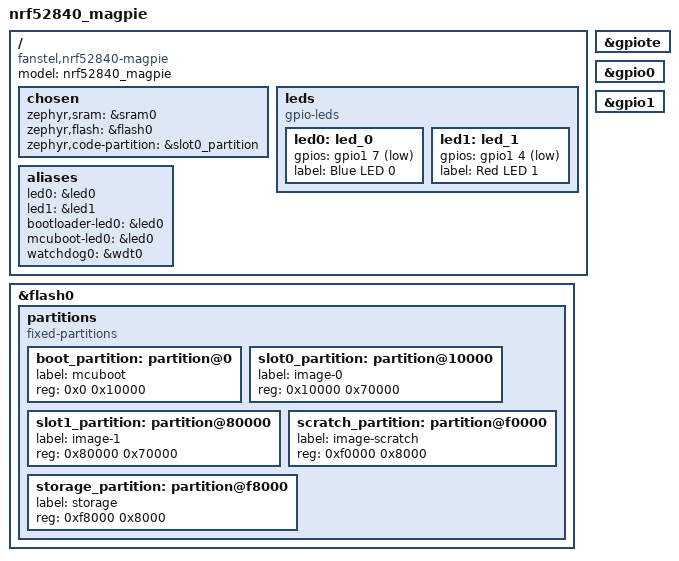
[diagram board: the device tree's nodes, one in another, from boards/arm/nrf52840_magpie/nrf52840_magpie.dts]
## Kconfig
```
# Copyright (c) 2021 Nordic Semiconductor ASA
# SPDX-License-Identifier: Apache-2.0

mainmenu "Nordic SYSTEM_OFF demo"

config APP_RETENTION
	bool "State retention in system off"
	depends on (SOC_COMPATIBLE_NRF52X || SOC_NRF52840) && CRC
	help
	  On some Nordic chips this application supports retaining
	  memory while in system off.  Select this to enable the
	  feature.

source "Kconfig.zephyr"
```

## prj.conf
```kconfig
# Copyright (c) 2024 Nordic Semiconductor ASA
# SPDX-License-Identifier: Apache-2.0

CONFIG_PM_DEVICE=y
CONFIG_GPIO=y
CONFIG_CRC=y
CONFIG_POWEROFF=y

CONFIG_CORTEX_M_DEBUG_MONITOR_HOOK=y
CONFIG_DEBUG_THREAD_INFO=y
CONFIG_SEGGER_DEBUGMON=y
CONFIG_DEBUG_OPTIMIZATIONS=y
CONFIG_KERNEL_BIN_NAME="nrf52840_magpie"

CONFIG_CLOCK_CONTROL_NRF_K32SRC_EXT_FULL_SWING=y
CONFIG_CLOCK_CONTROL_NRF_K32SRC_20PPM=y
CONFIG_CLOCK_CONTROL_FIXED_RATE_CLOCK=y

# Enable retained data feature
CONFIG_APP_RETENTION=y
```

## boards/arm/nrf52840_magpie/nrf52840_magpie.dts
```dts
// Copyright (c) 2024 Nordic Semiconductor ASA
// SPDX-License-Identifier: Apache-2.0

/dts-v1/;
#include <nordic/nrf52840_qfaa.dtsi>

/ {
	model = "nrf52840_magpie";
	compatible = "fanstel,nrf52840-magpie";

	chosen {
		zephyr,sram = &sram0;
		zephyr,flash = &flash0;
		zephyr,code-partition = &slot0_partition;
	};

	leds {
		compatible = "gpio-leds";
		led0: led_0 {
			gpios = <&gpio1 7 GPIO_ACTIVE_LOW>;
			label = "Blue LED 0";
		};
		led1: led_1 {
			gpios = <&gpio1 4 GPIO_ACTIVE_LOW>;
			label = "Red LED 1";
		};
	};

	aliases {
		led0 = &led0;
		led1 = &led1;
		bootloader-led0 = &led0;
		mcuboot-led0 = &led0;
		watchdog0 = &wdt0;
	};
};

&gpiote {
	status = "okay";
};

&gpio0 {
	status = "okay";
};

&gpio1 {
	status = "okay";
};

&flash0 {
	partitions {
		compatible = "fixed-partitions";
		#address-cells = <1>;
		#size-cells = <1>;

		boot_partition: partition@0 {
			label = "mcuboot";
			reg = <0x0 0x10000>;
		};
		slot0_partition: partition@10000 {
			label = "image-0";
			reg = <0x10000 0x70000>;
		};
		slot1_partition: partition@80000 {
			label = "image-1";
			reg = <0x80000 0x70000>;
		};
		scratch_partition: partition@f0000 {
			label = "image-scratch";
			reg = <0xf0000 0x8000>;
		};
		storage_partition: partition@f8000 {
			label = "storage";
			reg = <0xf8000 0x8000>;
		};
	};
};
```

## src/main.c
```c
/*
 * Copyright (c) 2019 Nordic Semiconductor ASA
 *
 * SPDX-License-Identifier: Apache-2.0
 */

#include "retained.h"

#include <inttypes.h>
#include <stdio.h>

#include <zephyr/device.h>
#include <zephyr/drivers/gpio.h>
#include <zephyr/kernel.h>
#include <zephyr/pm/device.h>
#include <zephyr/sys/poweroff.h>
#include <zephyr/sys/util.h>

#include <hal/nrf_gpio.h>

/* 1000 msec = 1 sec */
#define SLEEP_TIME_MS   100
/* The devicetree node identifier for the "led0" alias. */
#define LED0_NODE DT_ALIAS(led0)
/* The devicetree node identifier for the "led0" alias. */
#define LED1_NODE DT_ALIAS(led1)

static const struct gpio_dt_spec led_blue = GPIO_DT_SPEC_GET(LED0_NODE, gpios);
static const struct gpio_dt_spec led_red = GPIO_DT_SPEC_GET(LED1_NODE, gpios);
// static const struct gpio_dt_spec sw0 = GPIO_DT_SPEC_GET(DT_ALIAS(sw0), gpios);

/* LED pin definitions (from devicetree) */
#define LED_BLUE_PIN  7   /* P1.7 */
#define LED_RED_PIN   4   /* P1.4 */

/**
 * @brief Disconnect all GPIO pins to High-Z state
 * 
 * Sets all GPIO pins to input with no pull resistors (high impedance).
 * This prevents the nRF from interfering with shared bus lines when sleeping.
 * Exceptions:
 *   - P1.13: Output LOW
 *   - P1.14: Input
 *   - P1.4 (Red LED): Preserved
 *   - P1.7 (Blue LED): Preserved
 */
static void disconnect_all_gpios(void)
{
	/* Port 0: pins 0-31 */
	for (uint32_t pin = 0; pin < 32; pin++) {
		nrf_gpio_cfg_default(NRF_GPIO_PIN_MAP(0, pin));
	}
	/* Port 1: pins 0-15 (nRF52840 has 48 GPIOs total) */
	for (uint32_t pin = 0; pin < 16; pin++) {
		/* Skip P1.13, P1.14, and LED pins */
		if (pin == 13 || pin == 14 || pin == LED_BLUE_PIN || pin == LED_RED_PIN) {
			continue;
		}
		nrf_gpio_cfg_default(NRF_GPIO_PIN_MAP(1, pin));
	}

	/* P1.13: Output, default LOW */
	nrf_gpio_cfg_output(NRF_GPIO_PIN_MAP(1, 13));
	nrf_gpio_pin_clear(NRF_GPIO_PIN_MAP(1, 13));

	/* P1.14: Input (no pull) */
	nrf_gpio_cfg_input(NRF_GPIO_PIN_MAP(1, 14), NRF_GPIO_PIN_NOPULL);
}

int main(void)
{
	int ret;

	if (!gpio_is_ready_dt(&led_blue)) {return 0;}
	if (!gpio_is_ready_dt(&led_red)) {return 0;}

	ret = gpio_pin_configure_dt(&led_blue, GPIO_OUTPUT_ACTIVE);
	if (ret < 0) {return 0;}

	ret = gpio_pin_configure_dt(&led_red, GPIO_OUTPUT_ACTIVE);
	if (ret < 0) {return 0;}

	ret = gpio_pin_set_dt(&led_red, 1);
	ret = gpio_pin_set_dt(&led_blue, 1);

	

	// int rc;
	// const struct device *const cons = DEVICE_DT_GET(DT_CHOSEN(zephyr_console));

	// if (!device_is_ready(cons)) {
	// 	printf("%s: device not ready.\n", cons->name);
	// 	return 0;
	// }

	//printf("\n%s Turning system off Demo\n", CONFIG_BOARD);

	if (IS_ENABLED(CONFIG_APP_RETENTION)) {
		bool retained_ok = retained_validate();
		ret = gpio_pin_set_dt(&led_blue, 0);
		ret = gpio_pin_set_dt(&led_red, 0);

		/* Increment for this boot attempt and update. */
		retained.boots += 1;
		retained_update();

		// printf("Retained data: %s\n", retained_ok ? "valid" : "INVALID");
		// printf("Boot count: %u\n", retained.boots);
		// printf("Off count: %u\n", retained.off_count);
		// printf("Active Ticks: %" PRIu64 "\n", retained.uptime_sum);
	} else {
		// printf("Retained data not supported\n");
		ret = gpio_pin_set_dt(&led_red, 1);
	}

	// /* configure sw0 as input, interrupt as level active to allow wake-up */
	// rc = gpio_pin_configure_dt(&sw0, GPIO_INPUT);
	// if (rc < 0) {
	// 	printf("Could not configure sw0 GPIO (%d)\n", rc);
	// 	return 0;
	// }

	// rc = gpio_pin_interrupt_configure_dt(&sw0, GPIO_INT_LEVEL_ACTIVE);
	// if (rc < 0) {
	// 	printf("Could not configure sw0 GPIO interrupt (%d)\n", rc);
	// 	return 0;
	// }
	//printf("Testing LEDs ...\n");

	for (size_t i = 0; i < 5; i++)
	{
		ret = gpio_pin_toggle_dt(&led_blue);		
		if (ret < 0) {
			return 0;
		}
		ret = gpio_pin_toggle_dt(&led_red);		
		if (ret < 0) {
			return 0;
		}

		k_msleep(SLEEP_TIME_MS);
	}
	

	//printf("Entering system off\n");

	// rc = pm_device_action_run(cons, PM_DEVICE_ACTION_SUSPEND);
	// if (rc < 0) {
	// 	printf("Could not suspend console (%d)\n", rc);
	// 	return 0;
	// }

	

	if (IS_ENABLED(CONFIG_APP_RETENTION)) {
		/* Update the retained state */
		retained.off_count += 1;
		retained_update();
	}

	/* Set all GPIOs to High-Z (disconnected) before sleep
	 * This prevents interference with shared bus lines to other MCU */
	disconnect_all_gpios();

	/* Turn on Blue LED, turn off Red LED after disconnect */
	gpio_pin_set_dt(&led_blue, 1);
	gpio_pin_set_dt(&led_red, 0);

	//sys_poweroff();

	return 0;
}
```
